AUTOSAR XML (schema 4-2-2)
package /MICROSAR_SWCS_DEV/EcuM_swc/ComponentTypes
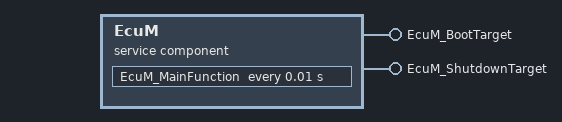
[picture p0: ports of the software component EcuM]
  service sw component type EcuM
    provide port EcuM_BootTarget: provided-com-specs=[{operation=GetBootTarget, queue-length=1}, {operation=SelectBootTarget, queue-length=1}], provided-interface=EcuM_BootTarget
    provide port EcuM_ShutdownTarget: provided-interface=EcuM_ShutdownTarget
      provided-com-specs:
        operation=GetLastShutdownTarget, queue-length=1
        operation=GetShutdownCause, queue-length=1
        operation=GetShutdownTarget, queue-length=1
        operation=SelectShutdownCause, queue-length=1
        operation=SelectShutdownTarget, queue-length=1
    behavior EcuMInternalBehavior: included-data-type-set=data-type=[EcuM_BootTargetType, EcuM_ModeType, EcuM_ShutdownCauseType, EcuM_StateType, EcuM_TimeType, EcuM_UserType]
      timing event Timer_EcuM_MainFunction: start-on-event=EcuM_MainFunction, period=0.01
      7 x operation invoked event:
        OpEventGetBootTarget_GetBootTarget_EcuM_BootTarget: start-on-event=GetBootTarget, operation=EcuM_BootTarget.GetBootTarget
        OpEventGetLastShutdownTarget_GetLastShutdownTarget_EcuM_ShutdownTarget: start-on-event=GetLastShutdownTarget, operation=EcuM_ShutdownTarget.GetLastShutdownTarget
        OpEventGetShutdownCause_GetShutdownCause_EcuM_ShutdownTarget: start-on-event=GetShutdownCause, operation=EcuM_ShutdownTarget.GetShutdownCause
        OpEventGetShutdownTarget_GetShutdownTarget_EcuM_ShutdownTarget: start-on-event=GetShutdownTarget, operation=EcuM_ShutdownTarget.GetShutdownTarget
        OpEventSelectBootTarget_SelectBootTarget_EcuM_BootTarget: start-on-event=SelectBootTarget, operation=EcuM_BootTarget.SelectBootTarget
        OpEventSelectShutdownCause_SelectShutdownCause_EcuM_ShutdownTarget: start-on-event=SelectShutdownCause, operation=EcuM_ShutdownTarget.SelectShutdownCause
        OpEventSelectShutdownTarget_SelectShutdownTarget_EcuM_ShutdownTarget: start-on-event=SelectShutdownTarget, operation=EcuM_ShutdownTarget.SelectShutdownTarget
      port-api-options:
        enable-take-address=true, error-handling=NO-TRANSFORMER-ERROR-HANDLING, indirect-api=false, port=EcuM_BootTarget
        enable-take-address=true, error-handling=NO-TRANSFORMER-ERROR-HANDLING, indirect-api=false, port=EcuM_ShutdownTarget
      8 x runnable:
        EcuM_MainFunction
        GetBootTarget: can-be-invoked-concurrently=true, symbol=EcuM_GetBootTarget
        GetLastShutdownTarget: can-be-invoked-concurrently=true, symbol=EcuM_GetLastShutdownTarget
        GetShutdownCause: can-be-invoked-concurrently=true, symbol=EcuM_GetShutdownCause
        GetShutdownTarget: can-be-invoked-concurrently=true, symbol=EcuM_GetShutdownTarget
        SelectBootTarget: can-be-invoked-concurrently=true, symbol=EcuM_SelectBootTarget
        SelectShutdownCause: can-be-invoked-concurrently=true, symbol=EcuM_SelectShutdownCause
        SelectShutdownTarget: can-be-invoked-concurrently=true, symbol=EcuM_SelectShutdownTarget
  swc implementation EcuMImplementation: behavior=EcuMInternalBehavior
    code-descriptors:
      code Default: artifact-descriptors=autosar-engineering-object={short-label=Default, category=SWSRC}
